# STM32G071 register map
File version: 2.5
CPU: CM0 r0p1, little endian, MPU, no FPU, 2 interrupt priority bits
Registers are 32-bit, read-write, reset 0x0 unless marked. A register's access mark holds for its fields unless they carry their own. Offsets are from the block's base; [hi:lo] are bit positions; {n}, {i} and the like mark numbered series.

## DMAMUX
Base 0x40020800
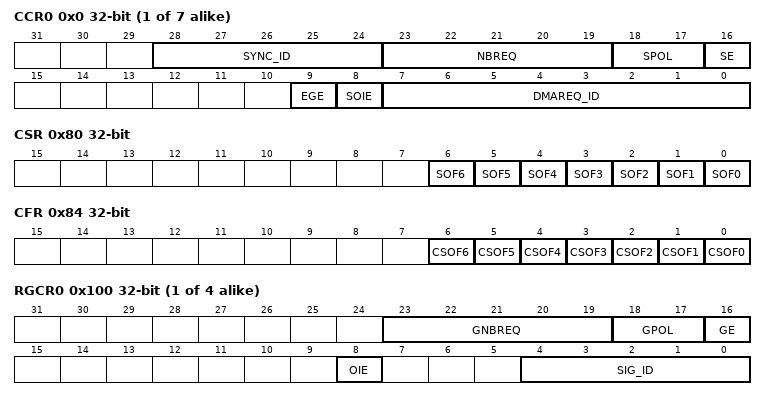
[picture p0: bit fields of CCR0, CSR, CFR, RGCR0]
{0x0+4i} CCR{i} (i=0..6) — DMA Multiplexer Channel {i} Control register
  [28:24] SYNC_ID — Synchronization input selected
  [23:19] NBREQ — Number of DMA requests to forward Defines the number of DMA requests forwarded before output event is generated. In synchronous mode, it also defines the number of DMA requests to forward after a synchronization event, then stop forwarding. The actual number of DMA requests forwarded is NBREQ+1. Note: This field can only be written when both SE and EGE bits are reset.
  [18:17] SPOL — Synchronization event type selector Defines the synchronization event on the selected synchronization input:
    0=NoEdge (No event, i.e. no synchronization nor detection); 1=RisingEdge; 2=FallingEdge; 3=BothEdges (Rising and falling edges)
  [16] SE — Synchronous operating mode enable/disable
    0=Disabled (Synchronization disabled); 1=Enabled (Synchronization enabled)
  [9] EGE — Event generation enable/disable
    0=Disabled (Event generation disabled); 1=Enabled (Event generation enabled)
  [8] SOIE — Interrupt enable at synchronization event overrun
    0=Disabled (Synchronization overrun interrupt disabled); 1=Enabled (Synchronization overrun interrupt enabled)
  [7:0] DMAREQ_ID — Input DMA request line selected
0x80 CSR ro — DMAMUX request line multiplexer interrupt channel status register
  [n] SOF{n} (n=0..6) — Synchronization Overrun Flag {n}
    0=NoSyncEvent (No synchronization event occured on a DMA request line multiplexer channel x, while the DMA request counter value is lower than NBREQ); 1=SyncEvent (Synchronization event occured on a DMA request line multiplexer channel x, while the DMA request counter value is lower than NBREQ)
0x84 CFR wo — DMAMUX request line multiplexer interrupt clear flag register
  [n] CSOF{n} (n=0..6) write-1-clears — Synchronization Clear Overrun Flag {n}
    1=Clear synchronization flag
{0x100+4i} RGCR{i} (i=0..3) — DMAMux - DMA request generator channel x control register
  [23:19] GNBREQ — Number of DMA requests to generate Defines the number of DMA requests generated after a trigger event, then stop generating. The actual number of generated DMA requests is GNBREQ+1. Note: This field can only be written when GE bit is reset.
  [18:17] GPOL — DMA request generator trigger event type selection Defines the trigger event on the selected DMA request trigger input
    0=NoEdge (No event, i.e. no detection nor generation); 1=RisingEdge; 2=FallingEdge; 3=BothEdges (Rising and falling edges)
  [16] GE — DMA request generator channel enable/disable
    0=Disabled (DMA request generation disabled); 1=Enabled (DMA request enabled)
  [8] OIE — Interrupt enable at trigger event overrun
    0=Disabled (Trigger overrun interrupt disabled); 1=Enabled (Trigger overrun interrupt enabled)
  [4:0] SIG_ID — DMA request trigger input selected
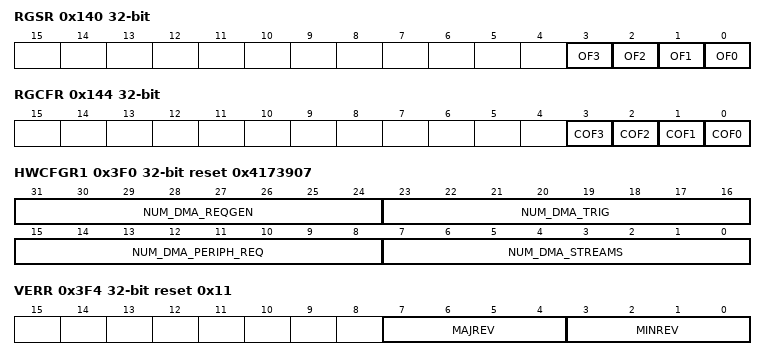
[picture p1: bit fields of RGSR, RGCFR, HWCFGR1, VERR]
0x140 RGSR ro — DMAMux - DMA request generator status register
  [n] OF{n} (n=0..3) — Generator Overrun Flag {n}
    0=NoTrigger (No new trigger event occured on DMA request generator channel x, before the request counter underrun); 1=Trigger (New trigger event occured on DMA request generator channel x, before the request counter underrun)
0x144 RGCFR wo — DMAMux - DMA request generator clear flag register
  [n] COF{n} (n=0..3) write-1-clears — Generator Clear Overrun Flag {n}
    1=Clear overrun flag
0x3EC HWCFGR2 ro reset 0x17 — DMAMUX hardware configuration 2 register
  [7:0] NUM_DMA_EXT_REQ — Number of DMA request trigger inputs
0x3F0 HWCFGR1 ro reset 0x4173907 — DMAMUX hardware configuration 1 register
  [31:24] NUM_DMA_REQGEN — number of DMA request generator channels
  [23:16] NUM_DMA_TRIG — number of synchronization inputs
  [15:8] NUM_DMA_PERIPH_REQ — number of DMA request lines from peripherals
  [7:0] NUM_DMA_STREAMS — number of DMA request line multiplexer (output) channels
0x3F4 VERR ro reset 0x11 — DMAMUX version register
  [7:4] MAJREV — Major IP revision
  [3:0] MINREV — Minor IP revision
0x3F8 IPIDR ro reset 0x100011 — DMAMUX IP identification register
  [31:0] ID — IP identification
0x3FC SIDR ro reset 0xA3C5DD01 — DMAMUX size identification register
  [31:0] SID — Size identification
